AUTOSAR XML (schema 4-0-3)
standard types defined: Boolean, UInt16
package /AUTOSAR_Platform/DataConstrs
  range DC_Boolean: raw 0..1
  range DC_UInt16: raw 0..65535
package /PATAC/MSM/ComponentTypes
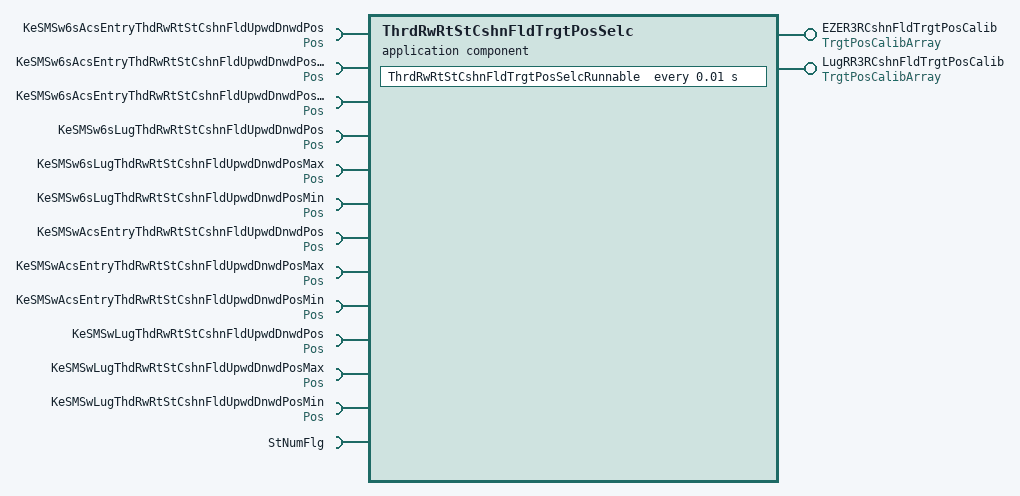
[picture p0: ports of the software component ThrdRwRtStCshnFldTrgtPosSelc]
  application sw component type ThrdRwRtStCshnFldTrgtPosSelc
    provide port EZER3RCshnFldTrgtPosCalib: nonqueued-sender-com-spec{data-element=TrgtPosArray, init-value=[4095, 4095, 4095]}, provided-interface=TrgtPosCalibArray
    provide port LugRR3RCshnFldTrgtPosCalib: nonqueued-sender-com-spec{data-element=TrgtPosArray, init-value=[4095, 4095, 4095]}, provided-interface=TrgtPosCalibArray
    13 x require port:
      KeSMSw6sAcsEntryThdRwRtStCshnFldUpwdDnwdPos: parameter-require-com-spec{init-value=0, parameter=Val}, required-interface=Pos
      KeSMSw6sAcsEntryThdRwRtStCshnFldUpwdDnwdPosMax: parameter-require-com-spec{init-value=0, parameter=Val}, required-interface=Pos
      KeSMSw6sAcsEntryThdRwRtStCshnFldUpwdDnwdPosMin: parameter-require-com-spec{init-value=0, parameter=Val}, required-interface=Pos
      KeSMSw6sLugThdRwRtStCshnFldUpwdDnwdPos: parameter-require-com-spec{init-value=4000, parameter=Val}, required-interface=Pos
      KeSMSw6sLugThdRwRtStCshnFldUpwdDnwdPosMax: parameter-require-com-spec{init-value=4000, parameter=Val}, required-interface=Pos
      KeSMSw6sLugThdRwRtStCshnFldUpwdDnwdPosMin: parameter-require-com-spec{init-value=4000, parameter=Val}, required-interface=Pos
      KeSMSwAcsEntryThdRwRtStCshnFldUpwdDnwdPos: parameter-require-com-spec{init-value=0, parameter=Val}, required-interface=Pos
      KeSMSwAcsEntryThdRwRtStCshnFldUpwdDnwdPosMax: parameter-require-com-spec{init-value=0, parameter=Val}, required-interface=Pos
      KeSMSwAcsEntryThdRwRtStCshnFldUpwdDnwdPosMin: parameter-require-com-spec{init-value=0, parameter=Val}, required-interface=Pos
      KeSMSwLugThdRwRtStCshnFldUpwdDnwdPos: parameter-require-com-spec{init-value=4000, parameter=Val}, required-interface=Pos
      KeSMSwLugThdRwRtStCshnFldUpwdDnwdPosMax: parameter-require-com-spec{init-value=4000, parameter=Val}, required-interface=Pos
      KeSMSwLugThdRwRtStCshnFldUpwdDnwdPosMin: parameter-require-com-spec{init-value=4000, parameter=Val}, required-interface=Pos
      StNumFlg: required-interface=StNumFlg
        required-com-specs:
          data-element=Is4s, filter=data-filter-type=ALWAYS, init-value=0
          data-element=Is6s, filter=data-filter-type=ALWAYS, init-value=0
          data-element=Is6s7s, filter=data-filter-type=ALWAYS, init-value=0
          data-element=Is7s, filter=data-filter-type=ALWAYS, init-value=0
    behavior ThrdRwRtStCshnFldTrgtPosSelc_InternalBehavior
      timing event TMT_Runnable: start-on-event=ThrdRwRtStCshnFldTrgtPosSelcRunnable, period=0.01
      runnable ThrdRwRtStCshnFldTrgtPosSelcRunnable
        data-receive-point-by-arguments:
          4 x access:
            REC_StNumFlg_Is4s: accessed-variable=StNumFlg.Is4s
            REC_StNumFlg_Is6s: accessed-variable=StNumFlg.Is6s
            REC_StNumFlg_Is6s7s: accessed-variable=StNumFlg.Is6s7s
            REC_StNumFlg_Is7s: accessed-variable=StNumFlg.Is7s
        data-send-points:
          access SEND_EZER3RCshnFldTrgtPosCalib_TrgtPosArray: accessed-variable=EZER3RCshnFldTrgtPosCalib.TrgtPosArray
          access SEND_LugRR3RCshnFldTrgtPosCalib_TrgtPosArray: accessed-variable=LugRR3RCshnFldTrgtPosCalib.TrgtPosArray
        12 x parameter access:
          PA_KeSMSw6sAcsEntryThdRwRtStCshnFldUpwdDnwdPos_Val: accessed-parameter=KeSMSw6sAcsEntryThdRwRtStCshnFldUpwdDnwdPos.Val
          PA_KeSMSw6sAcsEntryThdRwRtStCshnFldUpwdDnwdPosMax_Val: accessed-parameter=KeSMSw6sAcsEntryThdRwRtStCshnFldUpwdDnwdPosMax.Val
          PA_KeSMSw6sAcsEntryThdRwRtStCshnFldUpwdDnwdPosMin_Val: accessed-parameter=KeSMSw6sAcsEntryThdRwRtStCshnFldUpwdDnwdPosMin.Val
          PA_KeSMSw6sLugThdRwRtStCshnFldUpwdDnwdPos_Val: accessed-parameter=KeSMSw6sLugThdRwRtStCshnFldUpwdDnwdPos.Val
          PA_KeSMSw6sLugThdRwRtStCshnFldUpwdDnwdPosMax_Val: accessed-parameter=KeSMSw6sLugThdRwRtStCshnFldUpwdDnwdPosMax.Val
          PA_KeSMSw6sLugThdRwRtStCshnFldUpwdDnwdPosMin_Val: accessed-parameter=KeSMSw6sLugThdRwRtStCshnFldUpwdDnwdPosMin.Val
          PA_KeSMSwAcsEntryThdRwRtStCshnFldUpwdDnwdPos_Val: accessed-parameter=KeSMSwAcsEntryThdRwRtStCshnFldUpwdDnwdPos.Val
          PA_KeSMSwAcsEntryThdRwRtStCshnFldUpwdDnwdPosMax_Val: accessed-parameter=KeSMSwAcsEntryThdRwRtStCshnFldUpwdDnwdPosMax.Val
          PA_KeSMSwAcsEntryThdRwRtStCshnFldUpwdDnwdPosMin_Val: accessed-parameter=KeSMSwAcsEntryThdRwRtStCshnFldUpwdDnwdPosMin.Val
          PA_KeSMSwLugThdRwRtStCshnFldUpwdDnwdPos_Val: accessed-parameter=KeSMSwLugThdRwRtStCshnFldUpwdDnwdPos.Val
          PA_KeSMSwLugThdRwRtStCshnFldUpwdDnwdPosMax_Val: accessed-parameter=KeSMSwLugThdRwRtStCshnFldUpwdDnwdPosMax.Val
          PA_KeSMSwLugThdRwRtStCshnFldUpwdDnwdPosMin_Val: accessed-parameter=KeSMSwLugThdRwRtStCshnFldUpwdDnwdPosMin.Val
  swc implementation ThrdRwRtStCshnFldTrgtPosSelc_Implementation: behavior=ThrdRwRtStCshnFldTrgtPosSelc_InternalBehavior
    code-descriptors:
      code Default: artifact-descriptors=autosar-engineering-object={short-label=Default, category=SWSRC}
package /PATAC/MSM/ModeAdjust/CalPortInterface
  parameter interface Pos
    parameter data prototype Val: sw-calibration-access=READ-WRITE, type=UInt16
package /PATAC/MSM/ModeAdjust/DataType
  impl type TrgtPosCalibArray: category=ARRAY, sw-calibration-access=READ-ONLY, type-emitter=RTE  # 0:pos 1:max 2:min
    element Element: array-size=3, array-size-semantics=FIXED-SIZE, implementation-data-type=UInt16, invalid-value=0
package /PATAC/MSM/ModeAdjust/PortInterface
  sender receiver interface StNumFlg
    4 x data, all with type=Boolean:
      Is4s
      Is6s
      Is6s7s
      Is7s
    invalidation-policys:
      data-element=Is7s, handle-invalid=DONT-INVALIDATE
      data-element=Is6s, handle-invalid=DONT-INVALIDATE
      data-element=Is4s, handle-invalid=DONT-INVALIDATE
      data-element=Is6s7s, handle-invalid=DONT-INVALIDATE
  sender receiver interface TrgtPosCalibArray: invalidation-policy{data-element=TrgtPosArray, handle-invalid=DONT-INVALIDATE}
    data TrgtPosArray: type=TrgtPosCalibArray  # 0:Pos 1:Max 2:Min
